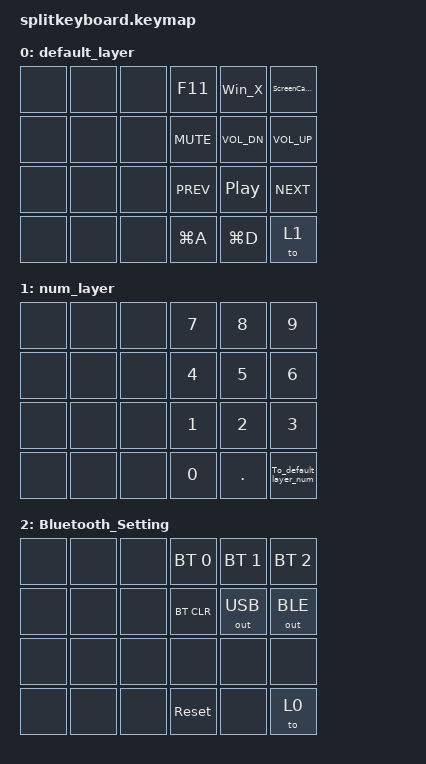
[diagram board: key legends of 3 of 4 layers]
/*
 * Copyright (c) 2020 The ZMK Contributors
 *
 * SPDX-License-Identifier: MIT
 */

#include <behaviors.dtsi>
#include <dt-bindings/zmk/bt.h>
#include <dt-bindings/zmk/keys.h>
#include <dt-bindings/zmk/outputs.h>

/ {
    macros {

        ScreenCapture: ScreenCapture {
            compatible = "zmk,behavior-macro";
            #binding-cells = <0>;
            bindings = <&kp LS(LG(S)) &sl 6>;
            label = "SCREENCAPTURE";
        };

        To_default_layer_num: To_default_layer_num {
            compatible = "zmk,behavior-macro";
            #binding-cells = <0>;
            bindings = <&kp ENTER &to 0>;
            label = "TO_DEFAULT_LAYER_NUM";
        };

        Win_X: Win_X {
            compatible = "zmk,behavior-macro";
            #binding-cells = <0>;
            bindings = <&kp LG(X) &sl 6>;
            label = "WIN_X";
        };
    };

    combos {
        compatible = "zmk,combos";

        Backspace {
            bindings = <&kp BACKSPACE>;
            key-positions = <3 7>;
            layers = <3 1>;
        };

        Bluetooth_Setting {
            bindings = <&to 5>;
            key-positions = <3 9>;
            layers = <0>;
        };

        Keyboard_Reset_Behavior {
            bindings = <&bootloader>;
            key-positions = <7 3>;
            layers = <5>;
        };
    };

    behaviors {
        new_behavior: new_behavior {
            compatible = "zmk,behavior-key-toggle";
            label = "NEW_BEHAVIOR";
            #binding-cells = <1>;
        };
    };

    keymap {
        compatible = "zmk,keymap";

        default_layer {
            bindings = <
&none  &none  &none  &kp F11    &Win_X         &ScreenCapture      
&none  &none  &none  &kp C_MUTE &kp C_VOL_DN   &kp C_VOL_UP               
&none  &none  &none  &kp C_PREV &kp C_PP       &kp C_NEXT
&none  &none  &none  &kp LG(A)  &kp LG(D)      &to 1       
            >;
        };

        num_layer {
            bindings = <
&none  &none  &none  &kp N7  &kp N8   &kp N9  
&none  &none  &none  &kp N4  &kp N5   &kp N6  
&none  &none  &none  &kp N1  &kp N2   &kp N3  
&none  &none  &none  &kp N0  &kp DOT  &To_default_layer_num
            >;
        };

        Bluetooth_Setting {
            bindings = <
&none  &none  &none  &bt BT_SEL 0   &bt BT_SEL 1    &bt BT_SEL 2     
&none  &none  &none  &bt BT_CLR     &out OUT_USB    &out OUT_BLE 
&none  &none  &none  &none          &none           &none 
&none  &none  &none  &sys_reset     &none           &to 0
            >;
        };

        layer_6 {
            bindings = <
&none  &none  &none  &none  &trans   &kp ESC  &kp ESC    
&none  &none  &none  &none  &trans   &trans   &trans  
&none  &none  &none  &none  &trans   &trans   &trans  
&none  &none  &none  &none  &trans   &trans   &trans  
            >;
        };
    };
};
